VERSION ""

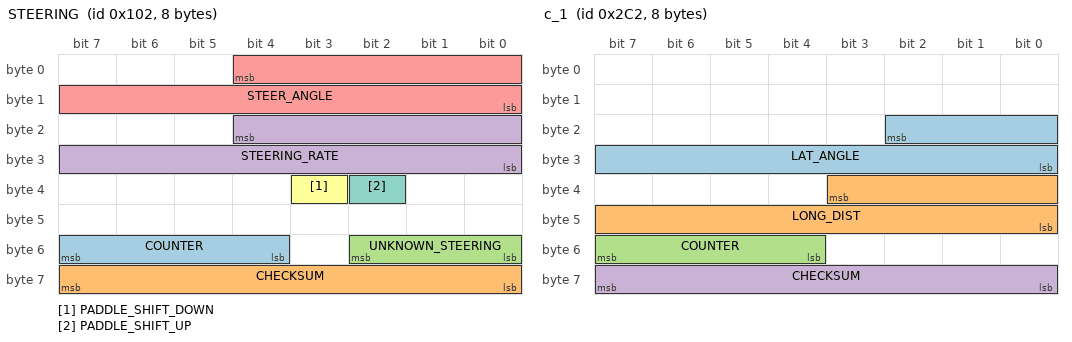
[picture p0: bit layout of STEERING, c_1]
BO_ 258 STEERING: 8 XXX
 SG_ COUNTER : 55|4@0+ (1,0) [0|15] "" XXX
 SG_ CHECKSUM : 63|8@0+ (1,0) [0|255] "" XXX
 SG_ UNKNOWN_STEERING : 50|3@0+ (1,0) [0|15] "" XXX
 SG_ STEERING_RATE : 20|13@0+ (0.3187251,-1305.498) [0|8191] "deg/s" XXX
 SG_ STEER_ANGLE : 4|13@0+ (0.3187251,-1307.888) [-360|360] "deg" XXX
 SG_ PADDLE_SHIFT_DOWN : 35|1@0+ (1,0) [0|1] "" XXX
 SG_ PADDLE_SHIFT_UP : 34|1@0+ (1,0) [0|1] "" XXX

BO_ 817 CAR_MODES: 8 XXX
 SG_ ECO_ON : 21|1@0+ (1,0) [0|1] "" XXX
 SG_ SPORT_ON : 22|1@0+ (1,0) [0|1] "" XXX

BO_ 706 c_1: 8 XXX
 SG_ LAT_ANGLE : 18|11@0+ (-0.00048828125,0.5) [-0.5|0.49951171875] "" XXX
 SG_ LONG_DIST : 35|12@0+ (0.0625,0) [0|255.93752] "m" XXX
 SG_ COUNTER : 55|4@0+ (1,0) [0|15] "" XXX
 SG_ CHECKSUM : 63|8@0+ (1,0) [0|255] "" XXX

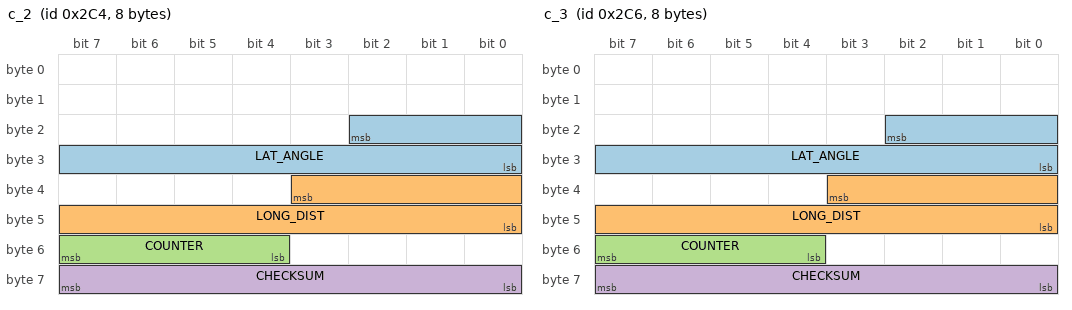
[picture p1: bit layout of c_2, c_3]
BO_ 708 c_2: 8 XXX
 SG_ LAT_ANGLE : 18|11@0+ (-0.00048828125,0.5) [-0.5|0.49951171875] "" XXX
 SG_ LONG_DIST : 35|12@0+ (0.0625,0) [0|255.93752] "m" XXX
 SG_ COUNTER : 55|4@0+ (1,0) [0|15] "" XXX
 SG_ CHECKSUM : 63|8@0+ (1,0) [0|255] "" XXX

BO_ 710 c_3: 8 XXX
 SG_ LAT_ANGLE : 18|11@0+ (-0.00048828125,0.5) [-0.5|0.49951171875] "" XXX
 SG_ LONG_DIST : 35|12@0+ (0.0625,0) [0|255.93752] "m" XXX
 SG_ COUNTER : 55|4@0+ (1,0) [0|15] "" XXX
 SG_ CHECKSUM : 63|8@0+ (1,0) [0|255] "" XXX

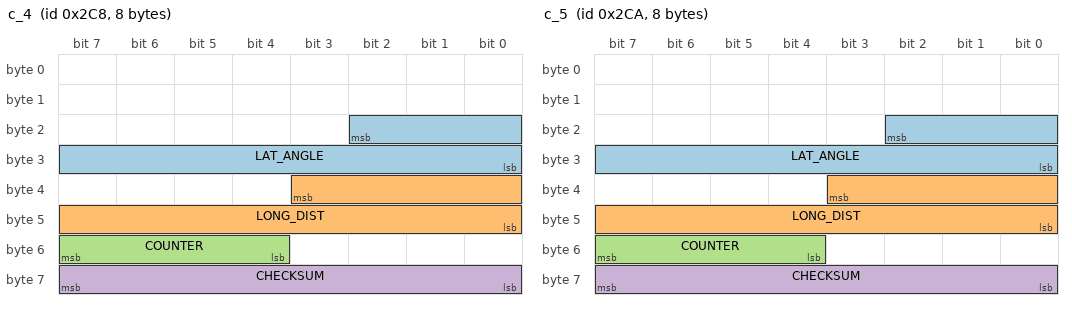
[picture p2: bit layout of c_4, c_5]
BO_ 712 c_4: 8 XXX
 SG_ LAT_ANGLE : 18|11@0+ (-0.00048828125,0.5) [-0.5|0.49951171875] "" XXX
 SG_ LONG_DIST : 35|12@0+ (0.0625,0) [0|255.93752] "m" XXX
 SG_ COUNTER : 55|4@0+ (1,0) [0|15] "" XXX
 SG_ CHECKSUM : 63|8@0+ (1,0) [0|255] "" XXX

BO_ 714 c_5: 8 XXX
 SG_ LAT_ANGLE : 18|11@0+ (-0.00048828125,0.5) [-0.5|0.49951171875] "" XXX
 SG_ LONG_DIST : 35|12@0+ (0.0625,0) [0|255.93752] "m" XXX
 SG_ COUNTER : 55|4@0+ (1,0) [0|15] "" XXX
 SG_ CHECKSUM : 63|8@0+ (1,0) [0|255] "" XXX

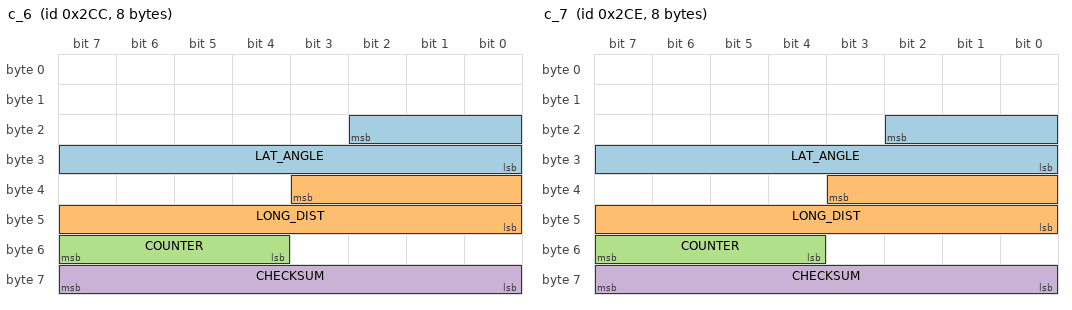
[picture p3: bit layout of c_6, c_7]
BO_ 716 c_6: 8 XXX
 SG_ LAT_ANGLE : 18|11@0+ (-0.00048828125,0.5) [-0.5|0.49951171875] "" XXX
 SG_ LONG_DIST : 35|12@0+ (0.0625,0) [0|255.93752] "m" XXX
 SG_ COUNTER : 55|4@0+ (1,0) [0|15] "" XXX
 SG_ CHECKSUM : 63|8@0+ (1,0) [0|255] "" XXX

BO_ 718 c_7: 8 XXX
 SG_ LAT_ANGLE : 18|11@0+ (-0.00048828125,0.5) [-0.5|0.49951171875] "" XXX
 SG_ LONG_DIST : 35|12@0+ (0.0625,0) [0|255.93752] "m" XXX
 SG_ COUNTER : 55|4@0+ (1,0) [0|15] "" XXX
 SG_ CHECKSUM : 63|8@0+ (1,0) [0|255] "" XXX

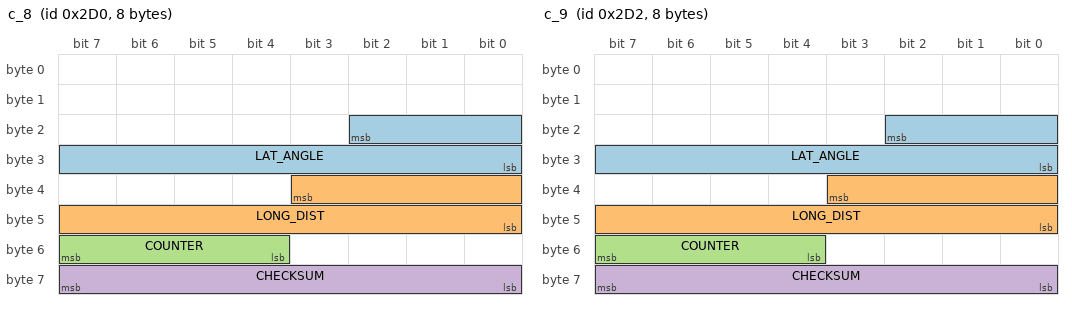
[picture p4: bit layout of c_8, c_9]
BO_ 720 c_8: 8 XXX
 SG_ LAT_ANGLE : 18|11@0+ (-0.00048828125,0.5) [-0.5|0.49951171875] "" XXX
 SG_ LONG_DIST : 35|12@0+ (0.0625,0) [0|255.93752] "m" XXX
 SG_ COUNTER : 55|4@0+ (1,0) [0|15] "" XXX
 SG_ CHECKSUM : 63|8@0+ (1,0) [0|255] "" XXX

BO_ 722 c_9: 8 XXX
 SG_ LAT_ANGLE : 18|11@0+ (-0.00048828125,0.5) [-0.5|0.49951171875] "" XXX
 SG_ LONG_DIST : 35|12@0+ (0.0625,0) [0|255.93752] "m" XXX
 SG_ COUNTER : 55|4@0+ (1,0) [0|15] "" XXX
 SG_ CHECKSUM : 63|8@0+ (1,0) [0|255] "" XXX

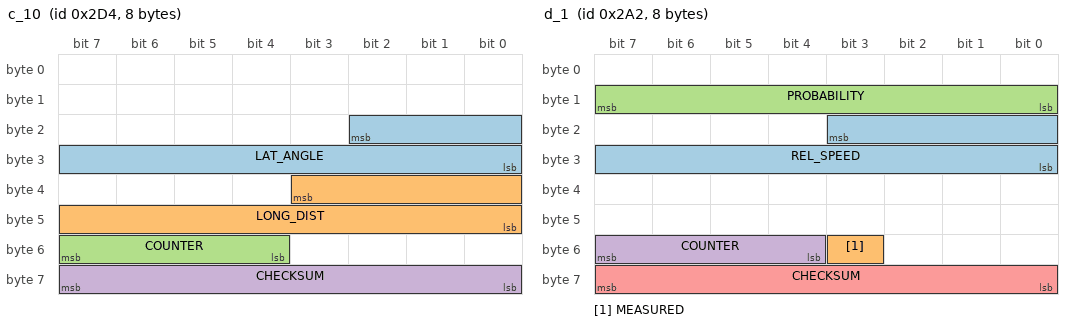
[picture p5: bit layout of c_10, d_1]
BO_ 724 c_10: 8 XXX
 SG_ LAT_ANGLE : 18|11@0+ (-0.00048828125,0.5) [-0.5|0.49951171875] "" XXX
 SG_ LONG_DIST : 35|12@0+ (0.0625,0) [0|255.93752] "m" XXX
 SG_ COUNTER : 55|4@0+ (1,0) [0|15] "" XXX
 SG_ CHECKSUM : 63|8@0+ (1,0) [0|255] "" XXX

BO_ 674 d_1: 8 XXX
 SG_ REL_SPEED : 19|12@0+ (0.25,-128) [-128|127] "m/s" XXX
 SG_ MEASURED : 51|1@0+ (1,0) [0|1] "" XXX
 SG_ PROBABILITY : 15|8@0+ (1,0) [0|255] "" XXX
 SG_ COUNTER : 55|4@0+ (1,0) [0|15] "" XXX
 SG_ CHECKSUM : 63|8@0+ (1,0) [0|255] "" XXX

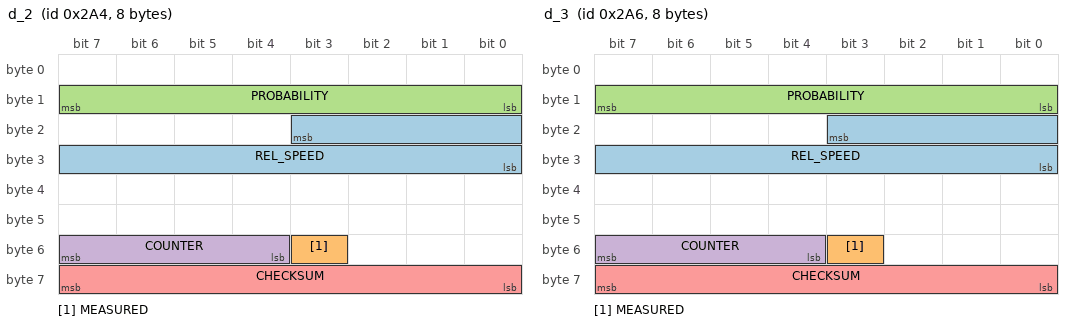
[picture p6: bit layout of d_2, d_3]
BO_ 676 d_2: 8 XXX
 SG_ REL_SPEED : 19|12@0+ (0.25,-128) [-128|127] "m/s" XXX
 SG_ MEASURED : 51|1@0+ (1,0) [0|1] "" XXX
 SG_ PROBABILITY : 15|8@0+ (1,0) [0|255] "" XXX
 SG_ COUNTER : 55|4@0+ (1,0) [0|15] "" XXX
 SG_ CHECKSUM : 63|8@0+ (1,0) [0|255] "" XXX

BO_ 678 d_3: 8 XXX
 SG_ REL_SPEED : 19|12@0+ (0.25,-128) [-128|127] "m/s" XXX
 SG_ MEASURED : 51|1@0+ (1,0) [0|1] "" XXX
 SG_ PROBABILITY : 15|8@0+ (1,0) [0|255] "" XXX
 SG_ COUNTER : 55|4@0+ (1,0) [0|15] "" XXX
 SG_ CHECKSUM : 63|8@0+ (1,0) [0|255] "" XXX

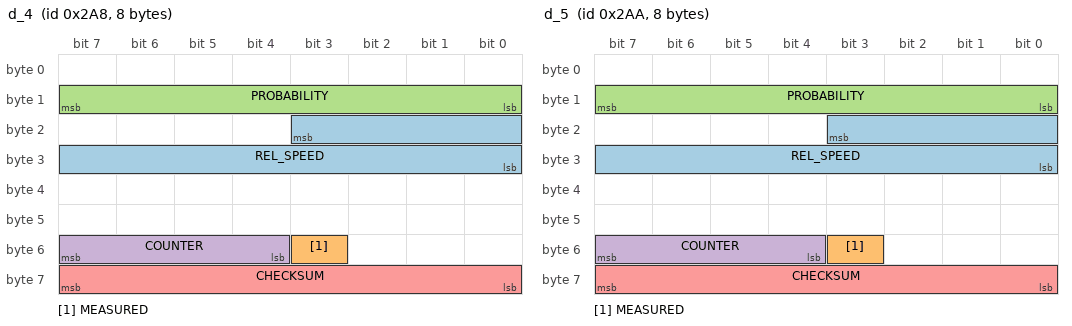
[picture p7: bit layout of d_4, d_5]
BO_ 680 d_4: 8 XXX
 SG_ REL_SPEED : 19|12@0+ (0.25,-128) [-128|127] "m/s" XXX
 SG_ MEASURED : 51|1@0+ (1,0) [0|1] "" XXX
 SG_ PROBABILITY : 15|8@0+ (1,0) [0|255] "" XXX
 SG_ COUNTER : 55|4@0+ (1,0) [0|15] "" XXX
 SG_ CHECKSUM : 63|8@0+ (1,0) [0|255] "" XXX

BO_ 682 d_5: 8 XXX
 SG_ REL_SPEED : 19|12@0+ (0.25,-128) [-128|127] "m/s" XXX
 SG_ MEASURED : 51|1@0+ (1,0) [0|1] "" XXX
 SG_ PROBABILITY : 15|8@0+ (1,0) [0|255] "" XXX
 SG_ COUNTER : 55|4@0+ (1,0) [0|15] "" XXX
 SG_ CHECKSUM : 63|8@0+ (1,0) [0|255] "" XXX

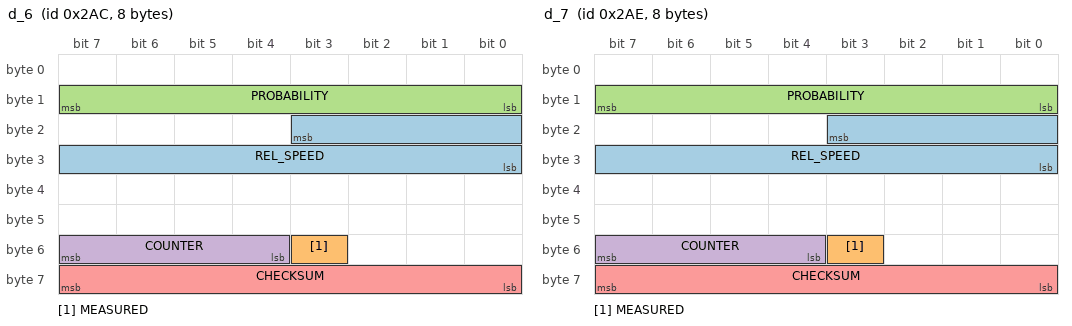
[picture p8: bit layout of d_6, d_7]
BO_ 684 d_6: 8 XXX
 SG_ REL_SPEED : 19|12@0+ (0.25,-128) [-128|127] "m/s" XXX
 SG_ MEASURED : 51|1@0+ (1,0) [0|1] "" XXX
 SG_ PROBABILITY : 15|8@0+ (1,0) [0|255] "" XXX
 SG_ COUNTER : 55|4@0+ (1,0) [0|15] "" XXX
 SG_ CHECKSUM : 63|8@0+ (1,0) [0|255] "" XXX

BO_ 686 d_7: 8 XXX
 SG_ REL_SPEED : 19|12@0+ (0.25,-128) [-128|127] "m/s" XXX
 SG_ MEASURED : 51|1@0+ (1,0) [0|1] "" XXX
 SG_ PROBABILITY : 15|8@0+ (1,0) [0|255] "" XXX
 SG_ COUNTER : 55|4@0+ (1,0) [0|15] "" XXX
 SG_ CHECKSUM : 63|8@0+ (1,0) [0|255] "" XXX

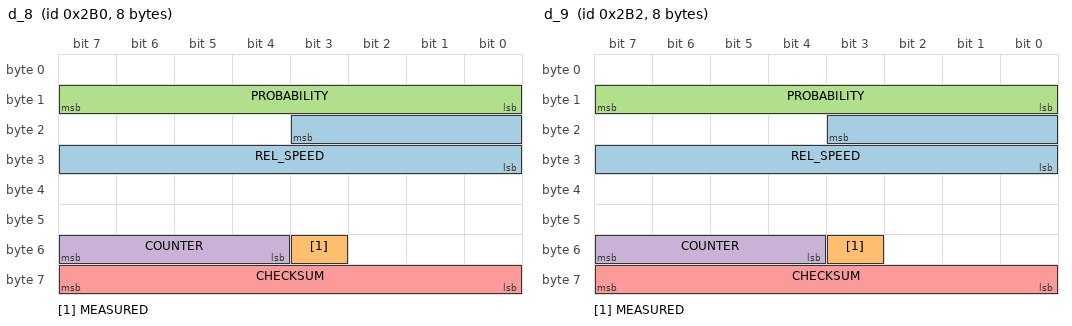
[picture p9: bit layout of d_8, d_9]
BO_ 688 d_8: 8 XXX
 SG_ REL_SPEED : 19|12@0+ (0.25,-128) [-128|127] "m/s" XXX
 SG_ MEASURED : 51|1@0+ (1,0) [0|1] "" XXX
 SG_ PROBABILITY : 15|8@0+ (1,0) [0|255] "" XXX
 SG_ COUNTER : 55|4@0+ (1,0) [0|15] "" XXX
 SG_ CHECKSUM : 63|8@0+ (1,0) [0|255] "" XXX

BO_ 690 d_9: 8 XXX
 SG_ REL_SPEED : 19|12@0+ (0.25,-128) [-128|127] "m/s" XXX
 SG_ MEASURED : 51|1@0+ (1,0) [0|1] "" XXX
 SG_ PROBABILITY : 15|8@0+ (1,0) [0|255] "" XXX
 SG_ COUNTER : 55|4@0+ (1,0) [0|15] "" XXX
 SG_ CHECKSUM : 63|8@0+ (1,0) [0|255] "" XXX

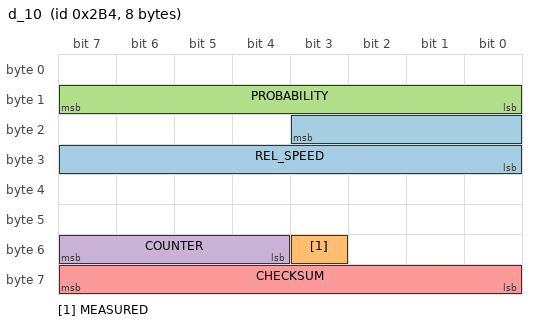
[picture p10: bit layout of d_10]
BO_ 692 d_10: 8 XXX
 SG_ REL_SPEED : 19|12@0+ (0.25,-128) [-128|127] "m/s" XXX
 SG_ MEASURED : 51|1@0+ (1,0) [0|1] "" XXX
 SG_ PROBABILITY : 15|8@0+ (1,0) [0|255] "" XXX
 SG_ COUNTER : 55|4@0+ (1,0) [0|15] "" XXX
 SG_ CHECKSUM : 63|8@0+ (1,0) [0|255] "" XXX
